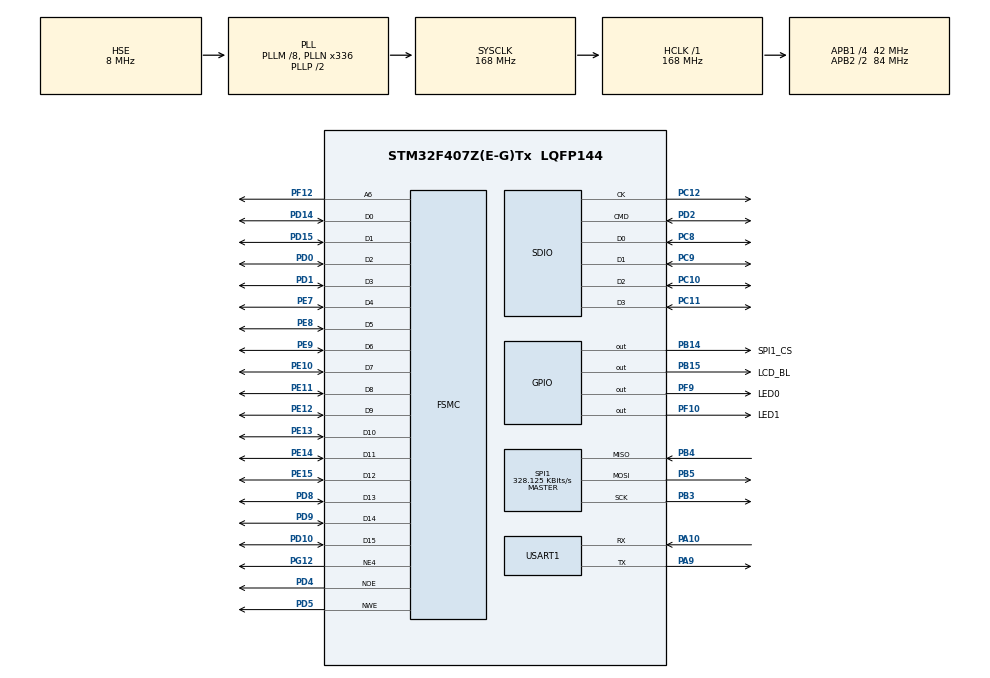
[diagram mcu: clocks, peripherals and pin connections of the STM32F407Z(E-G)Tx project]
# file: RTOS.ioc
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Dma.Request0=SDIO_TX
Dma.Request1=SDIO_RX
Dma.SDIO_RX.1.Direction=DMA_PERIPH_TO_MEMORY
Dma.SDIO_RX.1.FIFOMode=DMA_FIFOMODE_ENABLE
Dma.SDIO_RX.1.FIFOThreshold=DMA_FIFO_THRESHOLD_FULL
Dma.SDIO_RX.1.Instance=DMA2_Stream6
Dma.SDIO_RX.1.MemBurst=DMA_MBURST_INC4
Dma.SDIO_RX.1.MemDataAlignment=DMA_MDATAALIGN_WORD
Dma.SDIO_RX.1.MemInc=DMA_MINC_ENABLE
Dma.SDIO_RX.1.Mode=DMA_PFCTRL
Dma.SDIO_RX.1.PeriphBurst=DMA_PBURST_INC4
Dma.SDIO_RX.1.PeriphDataAlignment=DMA_PDATAALIGN_WORD
Dma.SDIO_RX.1.PeriphInc=DMA_PINC_DISABLE
Dma.SDIO_RX.1.Priority=DMA_PRIORITY_VERY_HIGH
Dma.SDIO_TX.0.Direction=DMA_MEMORY_TO_PERIPH
Dma.SDIO_TX.0.FIFOMode=DMA_FIFOMODE_ENABLE
Dma.SDIO_TX.0.FIFOThreshold=DMA_FIFO_THRESHOLD_FULL
Dma.SDIO_TX.0.Instance=DMA2_Stream3
Dma.SDIO_TX.0.MemBurst=DMA_MBURST_INC4
Dma.SDIO_TX.0.MemDataAlignment=DMA_MDATAALIGN_WORD
Dma.SDIO_TX.0.MemInc=DMA_MINC_ENABLE
Dma.SDIO_TX.0.Mode=DMA_PFCTRL
Dma.SDIO_TX.0.PeriphBurst=DMA_PBURST_INC4
Dma.SDIO_TX.0.PeriphDataAlignment=DMA_PDATAALIGN_WORD
Dma.SDIO_TX.0.PeriphInc=DMA_PINC_DISABLE
Dma.SDIO_TX.0.Priority=DMA_PRIORITY_VERY_HIGH
FATFS._CODE_PAGE=936
FATFS._USE_LFN=2
FREERTOS.Tasks01=defaultTask,24,256,StartDefaultTask,Default,NULL,Dynamic,NULL,NULL
FREERTOS.configCHECK_FOR_STACK_OVERFLOW=2
FREERTOS.configENABLE_FPU=1
FREERTOS.configUSE_MALLOC_FAILED_HOOK=1
FREERTOS.configUSE_NEWLIB_REENTRANT=0
FSMC.AddressSetupTime1=8
FSMC.BusTurnAroundDuration1=0
FSMC.DataSetupTime1=15
FSMC.ExtendedDataSetupTime1=15
FSMC.ExtendedMode1=FSMC_EXTENDED_MODE_ENABLE
Mcu.Family=STM32F4
Mcu.Name=STM32F407Z(E-G)Tx
Mcu.Package=LQFP144
NVIC.DMA2_Stream3_IRQn=true\:5\:0\:false\:false\:true\:true\:false\:true\:true
NVIC.DMA2_Stream6_IRQn=true\:5\:0\:false\:false\:true\:true\:false\:true\:true
NVIC.PriorityGroup=NVIC_PRIORITYGROUP_4
NVIC.SDIO_IRQn=true\:5\:0\:false\:false\:true\:true\:true\:true\:true
NVIC.TIM2_IRQn=true\:15\:0\:false\:false\:true\:false\:false\:true\:true
NVIC.TimeBase=TIM2_IRQn
NVIC.TimeBaseIP=TIM2
PA10.Mode=Asynchronous
PA10.Signal=USART1_RX
PA13.Mode=Serial_Wire
PA13.Signal=SYS_JTMS-SWDIO
PA14.Mode=Serial_Wire
PA14.Signal=SYS_JTCK-SWCLK
PA9.Mode=Asynchronous
PA9.Signal=USART1_TX
PB14.GPIO_Label=SPI1_CS
PB14.GPIO_Speed=GPIO_SPEED_FREQ_HIGH
PB14.PinState=GPIO_PIN_SET
PB14.Signal=GPIO_Output
PB15.GPIO_Label=LCD_BL
PB15.GPIO_PuPd=GPIO_NOPULL
PB15.GPIO_Speed=GPIO_SPEED_FREQ_VERY_HIGH
PB15.PinState=GPIO_PIN_SET
PB15.Signal=GPIO_Output
PB3.Mode=Full_Duplex_Master
PB3.Signal=SPI1_SCK
PB4.Mode=Full_Duplex_Master
PB4.Signal=SPI1_MISO
PB5.Mode=Full_Duplex_Master
PB5.Signal=SPI1_MOSI
PC10.Mode=SD_4_bits_Wide_bus
PC10.Signal=SDIO_D2
PC11.Mode=SD_4_bits_Wide_bus
PC11.Signal=SDIO_D3
PC12.Mode=SD_4_bits_Wide_bus
PC12.Signal=SDIO_CK
PC14-OSC32_IN.Mode=LSE-External-Oscillator
PC14-OSC32_IN.Signal=RCC_OSC32_IN
PC15-OSC32_OUT.Mode=LSE-External-Oscillator
PC15-OSC32_OUT.Signal=RCC_OSC32_OUT
PC8.Mode=SD_4_bits_Wide_bus
PC8.Signal=SDIO_D0
PC9.Mode=SD_4_bits_Wide_bus
PC9.Signal=SDIO_D1
PD0.Signal=FSMC_D2_DA2
PD1.Signal=FSMC_D3_DA3
PD10.Signal=FSMC_D15_DA15
PD14.Signal=FSMC_D0_DA0
PD15.Signal=FSMC_D1_DA1
PD2.Mode=SD_4_bits_Wide_bus
PD2.Signal=SDIO_CMD
PD4.Signal=FSMC_NOE
PD5.Signal=FSMC_NWE
PD8.Signal=FSMC_D13_DA13
PD9.Signal=FSMC_D14_DA14
PE10.Signal=FSMC_D7_DA7
PE11.Signal=FSMC_D8_DA8
PE12.Signal=FSMC_D9_DA9
PE13.Signal=FSMC_D10_DA10
PE14.Signal=FSMC_D11_DA11
PE15.Signal=FSMC_D12_DA12
PE7.Signal=FSMC_D4_DA4
PE8.Signal=FSMC_D5_DA5
PE9.Signal=FSMC_D6_DA6
PF10.GPIO_Label=LED1
PF10.GPIO_Speed=GPIO_SPEED_FREQ_MEDIUM
PF10.PinState=GPIO_PIN_SET
PF10.Signal=GPIO_Output
PF12.Signal=FSMC_A6
PF9.GPIO_Label=LED0
PF9.GPIO_Speed=GPIO_SPEED_FREQ_MEDIUM
PF9.PinState=GPIO_PIN_SET
PF9.Signal=GPIO_Output
PG12.Mode=NorPsramChipSelect4_1
PG12.Signal=FSMC_NE4
PH0-OSC_IN.Mode=HSE-External-Oscillator
PH0-OSC_IN.Signal=RCC_OSC_IN
PH1-OSC_OUT.Mode=HSE-External-Oscillator
PH1-OSC_OUT.Signal=RCC_OSC_OUT
ProjectManager.HeapSize=0x200
ProjectManager.StackSize=0x400
ProjectManager.TargetToolchain=CMake
RCC.48MHZClocksFreq_Value=48000000
RCC.AHBFreq_Value=168000000
RCC.APB1CLKDivider=RCC_HCLK_DIV4
RCC.APB1Freq_Value=42000000
RCC.APB1TimFreq_Value=84000000
RCC.APB2CLKDivider=RCC_HCLK_DIV2
RCC.APB2Freq_Value=84000000
RCC.APB2TimFreq_Value=168000000
RCC.CortexFreq_Value=168000000
RCC.HCLKFreq_Value=168000000
RCC.HSE_VALUE=8000000
RCC.HSI_VALUE=16000000
RCC.PLLM=8
RCC.PLLN=336
RCC.PLLQ=7
RCC.PLLSourceVirtual=RCC_PLLSOURCE_HSE
RCC.SYSCLKFreq_VALUE=168000000
RCC.SYSCLKSource=RCC_SYSCLKSOURCE_PLLCLK
RCC.VCOOutputFreq_Value=336000000
SH.FSMC_A6.0=FSMC_A6,A6_1
SH.FSMC_D0_DA0.0=FSMC_D0,16b-d1
SH.FSMC_D10_DA10.0=FSMC_D10,16b-d1
SH.FSMC_D11_DA11.0=FSMC_D11,16b-d1
SH.FSMC_D12_DA12.0=FSMC_D12,16b-d1
SH.FSMC_D13_DA13.0=FSMC_D13,16b-d1
SH.FSMC_D14_DA14.0=FSMC_D14,16b-d1
SH.FSMC_D15_DA15.0=FSMC_D15,16b-d1
SH.FSMC_D1_DA1.0=FSMC_D1,16b-d1
SH.FSMC_D2_DA2.0=FSMC_D2,16b-d1
SH.FSMC_D3_DA3.0=FSMC_D3,16b-d1
SH.FSMC_D4_DA4.0=FSMC_D4,16b-d1
SH.FSMC_D5_DA5.0=FSMC_D5,16b-d1
SH.FSMC_D6_DA6.0=FSMC_D6,16b-d1
SH.FSMC_D7_DA7.0=FSMC_D7,16b-d1
SH.FSMC_D8_DA8.0=FSMC_D8,16b-d1
SH.FSMC_D9_DA9.0=FSMC_D9,16b-d1
SH.FSMC_NOE.0=FSMC_NOE,Lcd1
SH.FSMC_NWE.0=FSMC_NWE,Lcd1
SPI1.BaudRatePrescaler=SPI_BAUDRATEPRESCALER_256
SPI1.CalculateBaudRate=328.125 KBits/s
SPI1.Direction=SPI_DIRECTION_2LINES
SPI1.Mode=SPI_MODE_MASTER
SPI1.VirtualType=VM_MASTER
USART1.VirtualMode=VM_ASYNC
VP_FATFS_VS_SDIO.Mode=SDIO
VP_FREERTOS_VS_CMSIS_V2.Mode=CMSIS_V2
VP_SYS_VS_tim2.Mode=TIM2
board=custom

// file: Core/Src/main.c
/* USER CODE BEGIN Header */
/**
  ******************************************************************************
  * @file           : main.c
  * @brief          : Main program body
  ******************************************************************************
  * @attention
  *
  * Copyright (c) 2026 STMicroelectronics.
  * All rights reserved.
  *
  * This software is licensed under terms that can be found in the LICENSE file
  * in the root directory of this software component.
  * If no LICENSE file comes with this software, it is provided AS-IS.
  *
  ******************************************************************************
  */
/* USER CODE END Header */
#include "main.h"
#include "cmsis_os.h"
#include "fatfs.h"

/* USER CODE BEGIN Includes */
#include "app_freertos.h"

/* USER CODE END Includes */

SD_HandleTypeDef hsd;
DMA_HandleTypeDef hdma_sdio_tx;
DMA_HandleTypeDef hdma_sdio_rx;

SPI_HandleTypeDef hspi1;

UART_HandleTypeDef huart1;

SRAM_HandleTypeDef hsram1;

/* Definitions for defaultTask */
osThreadId_t defaultTaskHandle;
const osThreadAttr_t defaultTask_attributes = {
  .name = "defaultTask",
  .stack_size = 256 * 4,
  .priority = (osPriority_t) osPriorityNormal,
};

void SystemClock_Config(void);
static void MX_GPIO_Init(void);
static void MX_DMA_Init(void);
static void MX_USART1_UART_Init(void);
static void MX_SDIO_SD_Init(void);
static void MX_FSMC_Init(void);
static void MX_SPI1_Init(void);
void StartDefaultTask(void *argument);

int main(void)
{

  /* MCU Configuration--------------------------------------------------------*/

  /* Reset of all peripherals, Initializes the Flash interface and the Systick. */
  HAL_Init();

  /* Configure the system clock */
  SystemClock_Config();

  /* Initialize all configured peripherals */
  MX_GPIO_Init();
  MX_DMA_Init();
  MX_USART1_UART_Init();
  MX_SDIO_SD_Init();
  MX_FSMC_Init();
  MX_SPI1_Init();
  MX_FATFS_Init();

  /* Init scheduler */
  osKernelInitialize();

  /* Create the thread(s) */
  /* creation of defaultTask */
  defaultTaskHandle = osThreadNew(StartDefaultTask, NULL, &defaultTask_attributes);

  /* USER CODE BEGIN RTOS_THREADS */
  App_FreeRTOS_Init();
  /* USER CODE END RTOS_THREADS */

  /* Start scheduler */
  osKernelStart();

  /* We should never get here as control is now taken by the scheduler */

  /* Infinite loop */
  while (1)
  {

  }
}

void SystemClock_Config(void)
{
  RCC_OscInitTypeDef RCC_OscInitStruct = {0};
  RCC_ClkInitTypeDef RCC_ClkInitStruct = {0};

  /** Configure the main internal regulator output voltage
  */
  __HAL_RCC_PWR_CLK_ENABLE();
  __HAL_PWR_VOLTAGESCALING_CONFIG(PWR_REGULATOR_VOLTAGE_SCALE1);

  /** Initializes the RCC Oscillators according to the specified parameters
  * in the RCC_OscInitTypeDef structure.
  */
  RCC_OscInitStruct.OscillatorType = RCC_OSCILLATORTYPE_HSE;
  RCC_OscInitStruct.HSEState = RCC_HSE_ON;
  RCC_OscInitStruct.PLL.PLLState = RCC_PLL_ON;
  RCC_OscInitStruct.PLL.PLLSource = RCC_PLLSOURCE_HSE;
  RCC_OscInitStruct.PLL.PLLM = 8;
  RCC_OscInitStruct.PLL.PLLN = 336;
  RCC_OscInitStruct.PLL.PLLP = RCC_PLLP_DIV2;
  RCC_OscInitStruct.PLL.PLLQ = 7;
  if (HAL_RCC_OscConfig(&RCC_OscInitStruct) != HAL_OK)
  {
    Error_Handler();
  }

  /** Initializes the CPU, AHB and APB buses clocks
  */
  RCC_ClkInitStruct.ClockType = RCC_CLOCKTYPE_HCLK|RCC_CLOCKTYPE_SYSCLK
                              |RCC_CLOCKTYPE_PCLK1|RCC_CLOCKTYPE_PCLK2;
  RCC_ClkInitStruct.SYSCLKSource = RCC_SYSCLKSOURCE_PLLCLK;
  RCC_ClkInitStruct.AHBCLKDivider = RCC_SYSCLK_DIV1;
  RCC_ClkInitStruct.APB1CLKDivider = RCC_HCLK_DIV4;
  RCC_ClkInitStruct.APB2CLKDivider = RCC_HCLK_DIV2;

  if (HAL_RCC_ClockConfig(&RCC_ClkInitStruct, FLASH_LATENCY_5) != HAL_OK)
  {
    Error_Handler();
  }
}

static void MX_SDIO_SD_Init(void)
{

  hsd.Instance = SDIO;
  hsd.Init.ClockEdge = SDIO_CLOCK_EDGE_RISING;
  hsd.Init.ClockBypass = SDIO_CLOCK_BYPASS_DISABLE;
  hsd.Init.ClockPowerSave = SDIO_CLOCK_POWER_SAVE_DISABLE;
  hsd.Init.BusWide = SDIO_BUS_WIDE_1B;
  hsd.Init.HardwareFlowControl = SDIO_HARDWARE_FLOW_CONTROL_DISABLE;
  hsd.Init.ClockDiv = 0;

}

static void MX_SPI1_Init(void)
{

  /* SPI1 parameter configuration*/
  hspi1.Instance = SPI1;
  hspi1.Init.Mode = SPI_MODE_MASTER;
  hspi1.Init.Direction = SPI_DIRECTION_2LINES;
  hspi1.Init.DataSize = SPI_DATASIZE_8BIT;
  hspi1.Init.CLKPolarity = SPI_POLARITY_LOW;
  hspi1.Init.CLKPhase = SPI_PHASE_1EDGE;
  hspi1.Init.NSS = SPI_NSS_SOFT;
  hspi1.Init.BaudRatePrescaler = SPI_BAUDRATEPRESCALER_256;
  hspi1.Init.FirstBit = SPI_FIRSTBIT_MSB;
  hspi1.Init.TIMode = SPI_TIMODE_DISABLE;
  hspi1.Init.CRCCalculation = SPI_CRCCALCULATION_DISABLE;
  hspi1.Init.CRCPolynomial = 10;
  if (HAL_SPI_Init(&hspi1) != HAL_OK)
  {
    Error_Handler();
  }

}

static void MX_USART1_UART_Init(void)
{

  huart1.Instance = USART1;
  huart1.Init.BaudRate = 115200;
  huart1.Init.WordLength = UART_WORDLENGTH_8B;
  huart1.Init.StopBits = UART_STOPBITS_1;
  huart1.Init.Parity = UART_PARITY_NONE;
  huart1.Init.Mode = UART_MODE_TX_RX;
  huart1.Init.HwFlowCtl = UART_HWCONTROL_NONE;
  huart1.Init.OverSampling = UART_OVERSAMPLING_16;
  if (HAL_UART_Init(&huart1) != HAL_OK)
  {
    Error_Handler();
  }

}

static void MX_DMA_Init(void)
{

  /* DMA controller clock enable */
  __HAL_RCC_DMA2_CLK_ENABLE();

  /* DMA interrupt init */
  /* DMA2_Stream3_IRQn interrupt configuration */
  HAL_NVIC_SetPriority(DMA2_Stream3_IRQn, 5, 0);
  HAL_NVIC_EnableIRQ(DMA2_Stream3_IRQn);
  /* DMA2_Stream6_IRQn interrupt configuration */
  HAL_NVIC_SetPriority(DMA2_Stream6_IRQn, 5, 0);
  HAL_NVIC_EnableIRQ(DMA2_Stream6_IRQn);

}

static void MX_GPIO_Init(void)
{
  GPIO_InitTypeDef GPIO_InitStruct = {0};

  /* GPIO Ports Clock Enable */
  __HAL_RCC_GPIOC_CLK_ENABLE();
  __HAL_RCC_GPIOF_CLK_ENABLE();
  __HAL_RCC_GPIOH_CLK_ENABLE();
  __HAL_RCC_GPIOE_CLK_ENABLE();
  __HAL_RCC_GPIOB_CLK_ENABLE();
  __HAL_RCC_GPIOD_CLK_ENABLE();
  __HAL_RCC_GPIOA_CLK_ENABLE();
  __HAL_RCC_GPIOG_CLK_ENABLE();

  /*Configure GPIO pin Output Level */
  HAL_GPIO_WritePin(GPIOF, LED0_Pin|LED1_Pin, GPIO_PIN_SET);

  /*Configure GPIO pin Output Level */
  HAL_GPIO_WritePin(GPIOB, SPI1_CS_Pin|LCD_BL_Pin, GPIO_PIN_SET);

  /*Configure GPIO pins : LED0_Pin LED1_Pin */
  GPIO_InitStruct.Pin = LED0_Pin|LED1_Pin;
  GPIO_InitStruct.Mode = GPIO_MODE_OUTPUT_PP;
  GPIO_InitStruct.Pull = GPIO_NOPULL;
  GPIO_InitStruct.Speed = GPIO_SPEED_FREQ_MEDIUM;
  HAL_GPIO_Init(GPIOF, &GPIO_InitStruct);

  /*Configure GPIO pin : SPI1_CS_Pin */
  GPIO_InitStruct.Pin = SPI1_CS_Pin;
  GPIO_InitStruct.Mode = GPIO_MODE_OUTPUT_PP;
  GPIO_InitStruct.Pull = GPIO_NOPULL;
  GPIO_InitStruct.Speed = GPIO_SPEED_FREQ_HIGH;
  HAL_GPIO_Init(SPI1_CS_GPIO_Port, &GPIO_InitStruct);

  /*Configure GPIO pin : LCD_BL_Pin */
  GPIO_InitStruct.Pin = LCD_BL_Pin;
  GPIO_InitStruct.Mode = GPIO_MODE_OUTPUT_PP;
  GPIO_InitStruct.Pull = GPIO_NOPULL;
  GPIO_InitStruct.Speed = GPIO_SPEED_FREQ_VERY_HIGH;
  HAL_GPIO_Init(LCD_BL_GPIO_Port, &GPIO_InitStruct);

}

/* FSMC initialization function */
static void MX_FSMC_Init(void)
{

  FSMC_NORSRAM_TimingTypeDef Timing = {0};
  FSMC_NORSRAM_TimingTypeDef ExtTiming = {0};

  /** Perform the SRAM1 memory initialization sequence
  */
  hsram1.Instance = FSMC_NORSRAM_DEVICE;
  hsram1.Extended = FSMC_NORSRAM_EXTENDED_DEVICE;
  /* hsram1.Init */
  hsram1.Init.NSBank = FSMC_NORSRAM_BANK4;
  hsram1.Init.DataAddressMux = FSMC_DATA_ADDRESS_MUX_DISABLE;
  hsram1.Init.MemoryType = FSMC_MEMORY_TYPE_SRAM;
  hsram1.Init.MemoryDataWidth = FSMC_NORSRAM_MEM_BUS_WIDTH_16;
  hsram1.Init.BurstAccessMode = FSMC_BURST_ACCESS_MODE_DISABLE;
  hsram1.Init.WaitSignalPolarity = FSMC_WAIT_SIGNAL_POLARITY_LOW;
  hsram1.Init.WrapMode = FSMC_WRAP_MODE_DISABLE;
  hsram1.Init.WaitSignalActive = FSMC_WAIT_TIMING_BEFORE_WS;
  hsram1.Init.WriteOperation = FSMC_WRITE_OPERATION_ENABLE;
  hsram1.Init.WaitSignal = FSMC_WAIT_SIGNAL_DISABLE;
  hsram1.Init.ExtendedMode = FSMC_EXTENDED_MODE_ENABLE;
  hsram1.Init.AsynchronousWait = FSMC_ASYNCHRONOUS_WAIT_DISABLE;
  hsram1.Init.WriteBurst = FSMC_WRITE_BURST_DISABLE;
  hsram1.Init.PageSize = FSMC_PAGE_SIZE_NONE;
  /* Timing */
  Timing.AddressSetupTime = 8;
  Timing.AddressHoldTime = 15;
  Timing.DataSetupTime = 15;
  Timing.BusTurnAroundDuration = 0;
  Timing.CLKDivision = 16;
  Timing.DataLatency = 17;
  Timing.AccessMode = FSMC_ACCESS_MODE_A;
  /* ExtTiming */
  ExtTiming.AddressSetupTime = 15;
  ExtTiming.AddressHoldTime = 15;
  ExtTiming.DataSetupTime = 15;
  ExtTiming.BusTurnAroundDuration = 15;
  ExtTiming.CLKDivision = 16;
  ExtTiming.DataLatency = 17;
  ExtTiming.AccessMode = FSMC_ACCESS_MODE_A;

  if (HAL_SRAM_Init(&hsram1, &Timing, &ExtTiming) != HAL_OK)
  {
    Error_Handler( );
  }

}

void StartDefaultTask(void *argument)
{
  for(;;)
  {
    osDelay(1);
  }
}

void HAL_TIM_PeriodElapsedCallback(TIM_HandleTypeDef *htim)
{
  if (htim->Instance == TIM2)
  {
    HAL_IncTick();
  }
}

void Error_Handler(void)
{
  __disable_irq();
  while (1)
  {
  }
}
